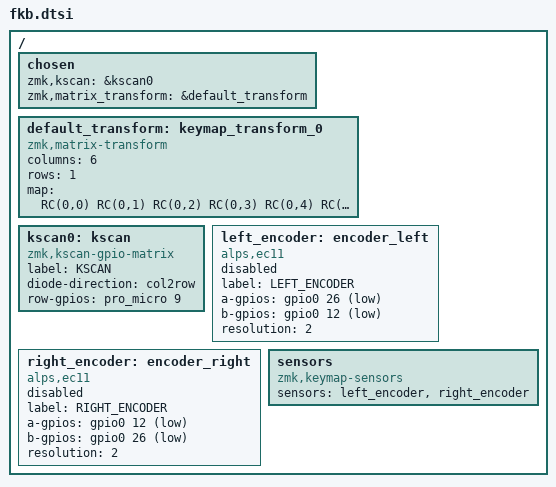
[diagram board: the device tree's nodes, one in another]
#include <dt-bindings/zmk/matrix_transform.h>

/ {
    chosen {
        zmk,kscan = &kscan0;
		zmk,matrix_transform = &default_transform;
    };

    default_transform: keymap_transform_0 {
		compatible = "zmk,matrix-transform";
		columns = <6>;
		rows = <1>;
		map = <
RC(0,0) RC(0,1) RC(0,2) RC(0,3) RC(0,4) RC(0,5)
	  >;
	};

    kscan0: kscan {
        compatible = "zmk,kscan-gpio-matrix";
        label = "KSCAN";

        diode-direction = "col2row";
        row-gpios
           = <&pro_micro 9 (GPIO_ACTIVE_HIGH | GPIO_PULL_DOWN)>
           ;
	};

	left_encoder: encoder_left {
		compatible = "alps,ec11";
    status = "disabled";
		label = "LEFT_ENCODER";
		a-gpios = <&gpio0 26 (GPIO_ACTIVE_LOW | GPIO_PULL_UP)>;
		b-gpios = <&gpio0 12 (GPIO_ACTIVE_LOW | GPIO_PULL_UP)>;
		resolution = <2>;
	};

	right_encoder: encoder_right {
		compatible = "alps,ec11";
    status = "disabled";
		label = "RIGHT_ENCODER";
		a-gpios = <&gpio0 12 (GPIO_ACTIVE_LOW | GPIO_PULL_UP)>;
		b-gpios = <&gpio0 26 (GPIO_ACTIVE_LOW | GPIO_PULL_UP)>;
		resolution = <2>;
	};

	sensors {
		compatible = "zmk,keymap-sensors";
		sensors = <&left_encoder &right_encoder>;
	};
};
